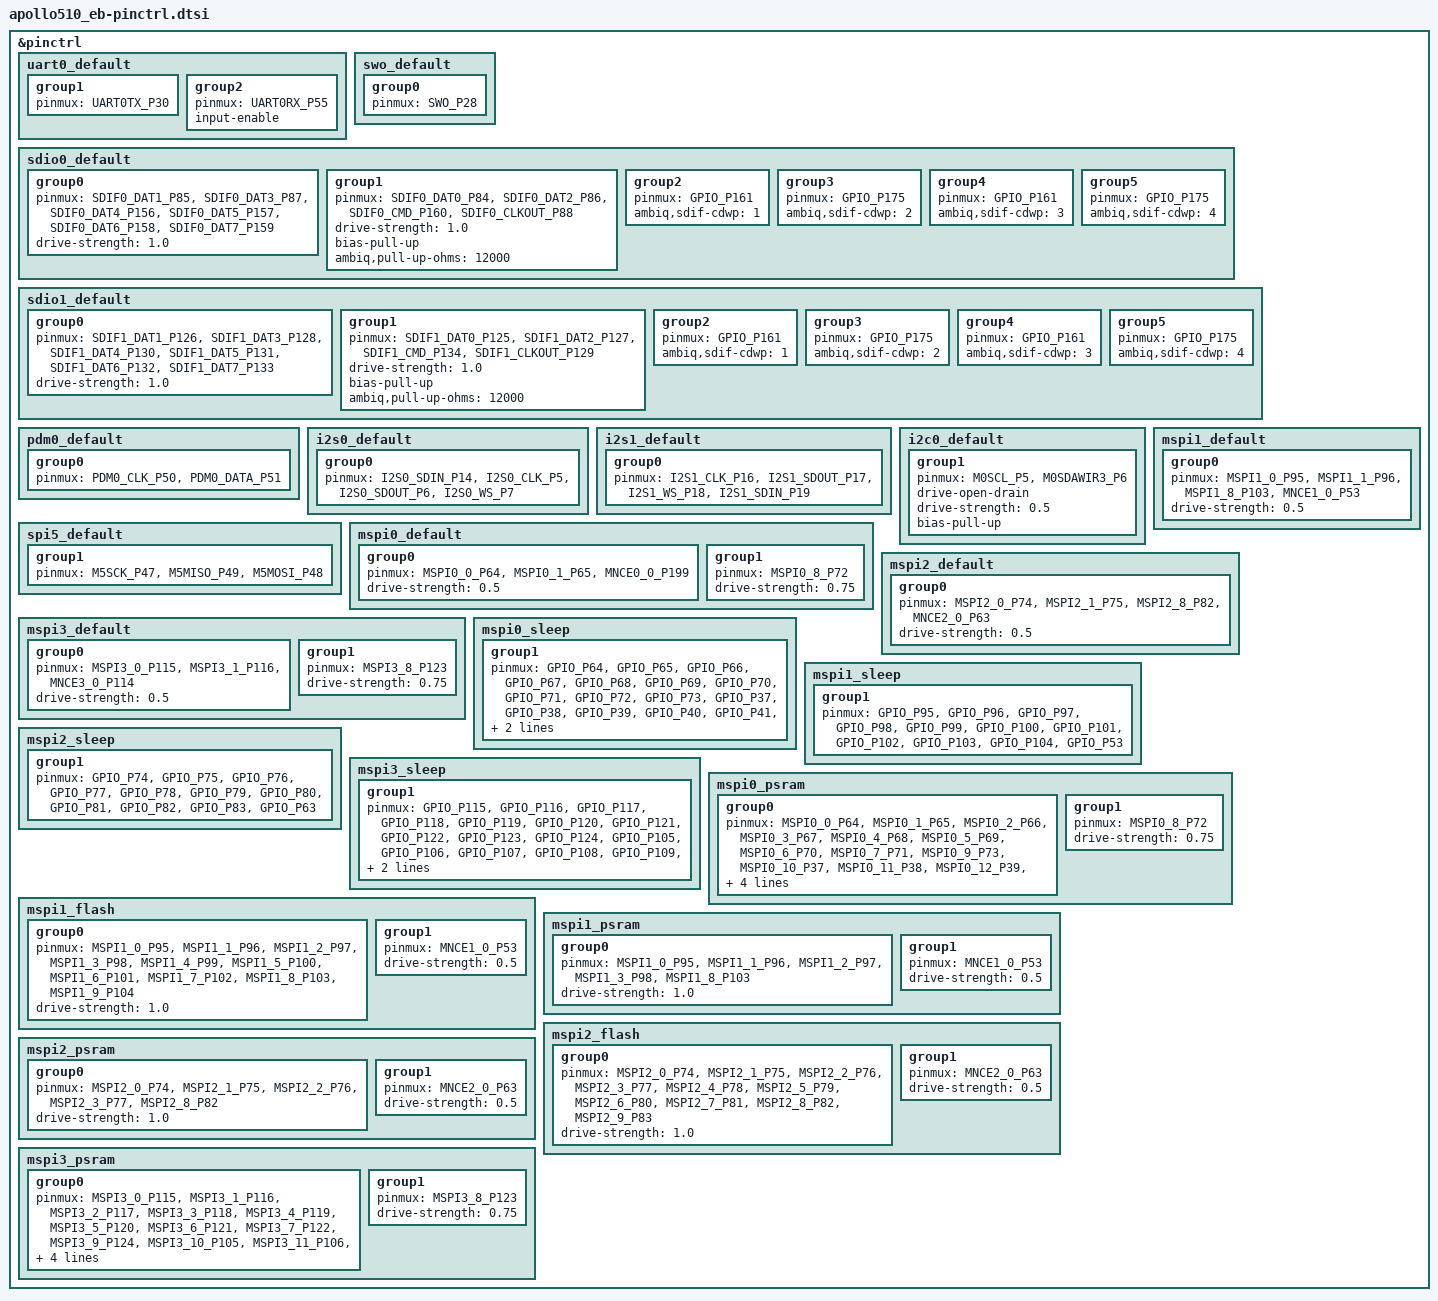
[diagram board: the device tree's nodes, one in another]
/*
 * Copyright (c) 2025 Ambiq Micro Inc.
 *
 * SPDX-License-Identifier: Apache-2.0
 */

#include <apollo510/ambiq-apollo510-pinmux.h>

&pinctrl {
	uart0_default: uart0_default {
		group1 {
			pinmux = <UART0TX_P30>;
		};
		group2 {
			pinmux = <UART0RX_P55>;
			input-enable;
		};
	};

	swo_default: swo_default {
		group0 {
			pinmux = <SWO_P28>;
		};
	};

	sdio0_default: sdio0_default {
		group0 {
			pinmux = <SDIF0_DAT1_P85>,
				 <SDIF0_DAT3_P87>,
				 <SDIF0_DAT4_P156>,
				 <SDIF0_DAT5_P157>,
				 <SDIF0_DAT6_P158>,
				 <SDIF0_DAT7_P159>;
				 drive-strength = "1.0";
		};
		group1 {
			pinmux = <SDIF0_DAT0_P84>,
				 <SDIF0_DAT2_P86>,
				 <SDIF0_CMD_P160>,
				 <SDIF0_CLKOUT_P88>;
				 drive-strength = "1.0";
				 bias-pull-up;
				 ambiq,pull-up-ohms = <12000>;
		};
		group2 {
			pinmux = <GPIO_P161>;
				 ambiq,sdif-cdwp = <1>;
		};
		group3 {
			pinmux = <GPIO_P175>;
				 ambiq,sdif-cdwp = <2>;
		};
		group4 {
			pinmux = <GPIO_P161>;
				 ambiq,sdif-cdwp = <3>;
		};
		group5 {
			pinmux = <GPIO_P175>;
				 ambiq,sdif-cdwp = <4>;
		};
	};

	sdio1_default: sdio1_default {
		group0 {
			pinmux = <SDIF1_DAT1_P126>,
				 <SDIF1_DAT3_P128>,
				 <SDIF1_DAT4_P130>,
				 <SDIF1_DAT5_P131>,
				 <SDIF1_DAT6_P132>,
				 <SDIF1_DAT7_P133>;
				 drive-strength = "1.0";
		};
		group1 {
			pinmux = <SDIF1_DAT0_P125>,
				 <SDIF1_DAT2_P127>,
				 <SDIF1_CMD_P134>,
				 <SDIF1_CLKOUT_P129>;
				 drive-strength = "1.0";
				 bias-pull-up;
				 ambiq,pull-up-ohms = <12000>;
		};
		group2 {
			pinmux = <GPIO_P161>;
				 ambiq,sdif-cdwp = <1>;
		};
		group3 {
			pinmux = <GPIO_P175>;
				 ambiq,sdif-cdwp = <2>;
		};
		group4 {
			pinmux = <GPIO_P161>;
				 ambiq,sdif-cdwp = <3>;
		};
		group5 {
			pinmux = <GPIO_P175>;
				 ambiq,sdif-cdwp = <4>;
		};
	};
	pdm0_default: pdm0_default {
		group0 {
			pinmux = <PDM0_CLK_P50>,
				 <PDM0_DATA_P51>;
		};
	};

	i2s0_default: i2s0_default {
		group0 {
			pinmux = <I2S0_SDIN_P14>,
				 <I2S0_CLK_P5>,
				 <I2S0_SDOUT_P6>,
				 <I2S0_WS_P7>;
		};
	};

	i2s1_default: i2s1_default {
		group0 {
			pinmux = <I2S1_CLK_P16>,
				 <I2S1_SDOUT_P17>,
				 <I2S1_WS_P18>,
				 <I2S1_SDIN_P19>;
		};
	};

	i2c0_default: i2c0_default {
		group1 {
			pinmux = <M0SCL_P5>, <M0SDAWIR3_P6>;
			drive-open-drain;
			drive-strength = "0.5";
			bias-pull-up;
		};
	};

	spi5_default: spi5_default {
		group1 {
			pinmux = <M5SCK_P47>, <M5MISO_P49>, <M5MOSI_P48>;
		};
	};

	mspi0_default: mspi0_default {
		group0 {
			pinmux = <MSPI0_0_P64>,
				 <MSPI0_1_P65>,
				 <MNCE0_0_P199>;
			drive-strength = "0.5";
		};
		group1 {
			pinmux = <MSPI0_8_P72>;
			drive-strength = "0.75";
		};
	};

	mspi1_default: mspi1_default {
		group0 {
			pinmux = <MSPI1_0_P95>,
				 <MSPI1_1_P96>,
				 <MSPI1_8_P103>,
				 <MNCE1_0_P53>;
			drive-strength = "0.5";
		};
	};

	mspi2_default: mspi2_default {
		group0 {
			pinmux = <MSPI2_0_P74>,
				 <MSPI2_1_P75>,
				 <MSPI2_8_P82>,
				 <MNCE2_0_P63>;
			drive-strength = "0.5";
		};
	};

	mspi3_default: mspi3_default {
		group0 {
			pinmux = <MSPI3_0_P115>,
				 <MSPI3_1_P116>,
				 <MNCE3_0_P114>;
			drive-strength = "0.5";
		};
		group1 {
			pinmux = <MSPI3_8_P123>;
			drive-strength = "0.75";
		};
	};

	mspi0_sleep: mspi0_sleep{
		group1 {
			pinmux = <GPIO_P64>,
				 <GPIO_P65>,
				 <GPIO_P66>,
				 <GPIO_P67>,
				 <GPIO_P68>,
				 <GPIO_P69>,
				 <GPIO_P70>,
				 <GPIO_P71>,
				 <GPIO_P72>,
				 <GPIO_P73>,
				 <GPIO_P37>,
				 <GPIO_P38>,
				 <GPIO_P39>,
				 <GPIO_P40>,
				 <GPIO_P41>,
				 <GPIO_P42>,
				 <GPIO_P43>,
				 <GPIO_P44>,
				 <GPIO_P45>,
				 <GPIO_P199>;
		};
	};

	mspi1_sleep: mspi1_sleep{
		group1 {
			pinmux = <GPIO_P95>,
				 <GPIO_P96>,
				 <GPIO_P97>,
				 <GPIO_P98>,
				 <GPIO_P99>,
				 <GPIO_P100>,
				 <GPIO_P101>,
				 <GPIO_P102>,
				 <GPIO_P103>,
				 <GPIO_P104>,
				 <GPIO_P53>;
		};
	};

	mspi2_sleep: mspi2_sleep{
		group1 {
			pinmux = <GPIO_P74>,
				 <GPIO_P75>,
				 <GPIO_P76>,
				 <GPIO_P77>,
				 <GPIO_P78>,
				 <GPIO_P79>,
				 <GPIO_P80>,
				 <GPIO_P81>,
				 <GPIO_P82>,
				 <GPIO_P83>,
				 <GPIO_P63>;
		};
	};

	mspi3_sleep: mspi3_sleep{
		group1 {
			pinmux = <GPIO_P115>,
				 <GPIO_P116>,
				 <GPIO_P117>,
				 <GPIO_P118>,
				 <GPIO_P119>,
				 <GPIO_P120>,
				 <GPIO_P121>,
				 <GPIO_P122>,
				 <GPIO_P123>,
				 <GPIO_P124>,
				 <GPIO_P105>,
				 <GPIO_P106>,
				 <GPIO_P107>,
				 <GPIO_P108>,
				 <GPIO_P109>,
				 <GPIO_P110>,
				 <GPIO_P111>,
				 <GPIO_P112>,
				 <GPIO_P113>,
				 <GPIO_P114>;
		};
	};

	mspi0_psram: mspi0_psram {
		group0 {
			pinmux = <MSPI0_0_P64>,   /* D0 */
				 <MSPI0_1_P65>,   /* D1 */
				 <MSPI0_2_P66>,   /* D2 */
				 <MSPI0_3_P67>,   /* D3 */
				 <MSPI0_4_P68>,   /* D4 */
				 <MSPI0_5_P69>,   /* D5 */
				 <MSPI0_6_P70>,   /* D6 */
				 <MSPI0_7_P71>,   /* D7 */
				 <MSPI0_9_P73>,   /* DQS0 */
				 <MSPI0_10_P37>,  /* D8 */
				 <MSPI0_11_P38>,  /* D9 */
				 <MSPI0_12_P39>,  /* D10 */
				 <MSPI0_13_P40>,  /* D11 */
				 <MSPI0_14_P41>,  /* D12 */
				 <MSPI0_15_P42>,  /* D13 */
				 <MSPI0_16_P43>,  /* D14 */
				 <MSPI0_17_P44>,  /* D15 */
				 <MSPI0_18_P45>,  /* DQS1 */
				 <MNCE0_0_P199>;  /* CE0 */
			drive-strength = "0.5";
		};
		group1 {
			pinmux = <MSPI0_8_P72>;   /* SCK */
			drive-strength = "0.75";
		};
	};

	mspi1_flash: mspi1_flash {
		group0 {
			pinmux = <MSPI1_0_P95>,
				 <MSPI1_1_P96>,
				 <MSPI1_2_P97>,
				 <MSPI1_3_P98>,
				 <MSPI1_4_P99>,
				 <MSPI1_5_P100>,
				 <MSPI1_6_P101>,
				 <MSPI1_7_P102>,
				 <MSPI1_8_P103>,
				 <MSPI1_9_P104>;
			drive-strength = "1.0";
		};
		group1 {
			pinmux = <MNCE1_0_P53>;
			drive-strength = "0.5";
		};
	};

	mspi1_psram: mspi1_psram {
		group0 {
			pinmux = <MSPI1_0_P95>,
				 <MSPI1_1_P96>,
				 <MSPI1_2_P97>,
				 <MSPI1_3_P98>,
				 <MSPI1_8_P103>;
			drive-strength = "1.0";
		};
		group1 {
			pinmux = <MNCE1_0_P53>;
			drive-strength = "0.5";
		};
	};

	mspi2_flash: mspi2_flash {
		group0 {
			pinmux = <MSPI2_0_P74>,
				 <MSPI2_1_P75>,
				 <MSPI2_2_P76>,
				 <MSPI2_3_P77>,
				 <MSPI2_4_P78>,
				 <MSPI2_5_P79>,
				 <MSPI2_6_P80>,
				 <MSPI2_7_P81>,
				 <MSPI2_8_P82>,
				 <MSPI2_9_P83>;
			drive-strength = "1.0";
		};
		group1 {
			pinmux = <MNCE2_0_P63>;
			drive-strength = "0.5";
		};
	};

	mspi2_psram: mspi2_psram {
		group0 {
			pinmux = <MSPI2_0_P74>,
				 <MSPI2_1_P75>,
				 <MSPI2_2_P76>,
				 <MSPI2_3_P77>,
				 <MSPI2_8_P82>;
			drive-strength = "1.0";
		};
		group1 {
			pinmux = <MNCE2_0_P63>;
			drive-strength = "0.5";
		};
	};

	mspi3_psram: mspi3_psram {
		group0 {
			pinmux = <MSPI3_0_P115>,   /* D0 */
				 <MSPI3_1_P116>,   /* D1 */
				 <MSPI3_2_P117>,   /* D2 */
				 <MSPI3_3_P118>,   /* D3 */
				 <MSPI3_4_P119>,   /* D4 */
				 <MSPI3_5_P120>,   /* D5 */
				 <MSPI3_6_P121>,   /* D6 */
				 <MSPI3_7_P122>,   /* D7 */
				 <MSPI3_9_P124>,   /* DQS0 */
				 <MSPI3_10_P105>,  /* D8 */
				 <MSPI3_11_P106>,  /* D9 */
				 <MSPI3_12_P107>,  /* D10 */
				 <MSPI3_13_P108>,  /* D11 */
				 <MSPI3_14_P109>,  /* D12 */
				 <MSPI3_15_P110>,  /* D13 */
				 <MSPI3_16_P111>,  /* D14 */
				 <MSPI3_17_P112>,  /* D15 */
				 <MSPI3_18_P113>,  /* DQS1 */
				 <MNCE3_0_P114>;   /* CE0 */
			drive-strength = "0.5";
		};
		group1 {
			pinmux = <MSPI3_8_P123>;   /* SCK */
			drive-strength = "0.75";
		};
	};
};
